# KD32F328CB register map
File version: 1.0
Registers are 32-bit, read-write, reset 0x0 unless marked. A register's access mark holds for its fields unless they carry their own. Offsets are from the block's base; [hi:lo] are bit positions.

## RCC — Reset and clock control
Base 0x40021000
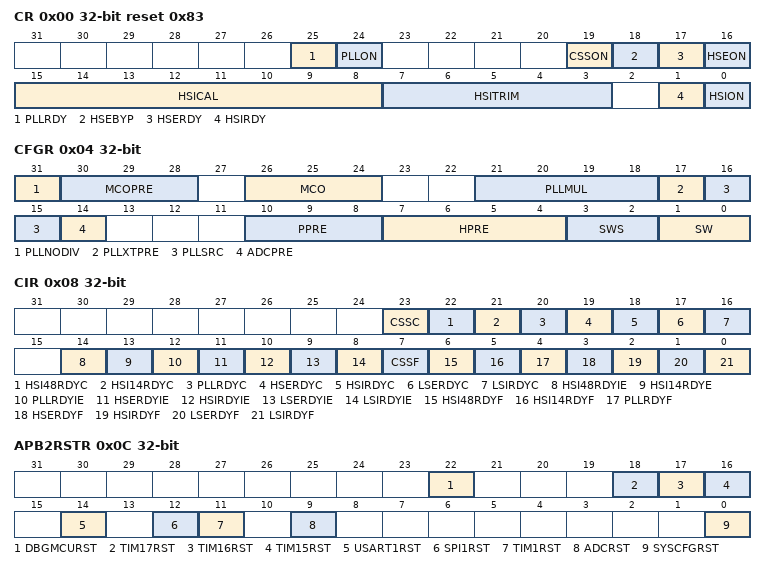
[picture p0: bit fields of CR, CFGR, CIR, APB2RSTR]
0x00 CR access per field reset 0x83 — Clock control register
  [25] PLLRDY ro — PLL clock ready flag
  [24] PLLON rw — PLL enable
  [19] CSSON rw — Clock Security System enable
  [18] HSEBYP rw — External High Speed clock Bypass
  [17] HSERDY ro — External High Speed clock ready flag
  [16] HSEON rw — External High Speed clock enable
  [15:8] HSICAL ro — Internal High Speed clock Calibration
  [7:3] HSITRIM rw — Internal High Speed clock trimming
  [1] HSIRDY ro — Internal High Speed clock ready flag
  [0] HSION rw — Internal High Speed clock enable
0x04 CFGR access per field — Clock configuration register (RCC_CFGR)
  [31] PLLNODIV rw — PLL clock not divided for MCO
  [30:28] MCOPRE rw — Microcontroller Clock Output Prescaler
  [26:24] MCO rw — Microcontroller clock output
  [21:18] PLLMUL rw — PLL Multiplication Factor
  [17] PLLXTPRE rw — HSE divider for PLL entry
  [16:15] PLLSRC rw — PLL input clock source
  [14] ADCPRE rw — ADC prescaler
  [10:8] PPRE rw — APB Low speed prescaler (APB1)
  [7:4] HPRE rw — AHB prescaler
  [3:2] SWS ro — System Clock Switch Status
  [1:0] SW rw — System clock Switch
0x08 CIR access per field — Clock interrupt register (RCC_CIR)
  [23] CSSC wo — Clock security system interrupt clear
  [22] HSI48RDYC wo — HSI48 Ready Interrupt Clear
  [21] HSI14RDYC wo — HSI 14 MHz Ready Interrupt Clear
  [20] PLLRDYC wo — PLL Ready Interrupt Clear
  [19] HSERDYC wo — HSE Ready Interrupt Clear
  [18] HSIRDYC wo — HSI Ready Interrupt Clear
  [17] LSERDYC wo — LSE Ready Interrupt Clear
  [16] LSIRDYC wo — LSI Ready Interrupt Clear
  [14] HSI48RDYIE rw — HSI48 ready interrupt enable
  [13] HSI14RDYE rw — HSI14 ready interrupt enable
  [12] PLLRDYIE rw — PLL Ready Interrupt Enable
  [11] HSERDYIE rw — HSE Ready Interrupt Enable
  [10] HSIRDYIE rw — HSI Ready Interrupt Enable
  [9] LSERDYIE rw — LSE Ready Interrupt Enable
  [8] LSIRDYIE rw — LSI Ready Interrupt Enable
  [7] CSSF ro — Clock Security System Interrupt flag
  [6] HSI48RDYF ro — HSI48 ready interrupt flag
  [5] HSI14RDYF ro — HSI14 ready interrupt flag
  [4] PLLRDYF ro — PLL Ready Interrupt flag
  [3] HSERDYF ro — HSE Ready Interrupt flag
  [2] HSIRDYF ro — HSI Ready Interrupt flag
  [1] LSERDYF ro — LSE Ready Interrupt flag
  [0] LSIRDYF ro — LSI Ready Interrupt flag
0x0C APB2RSTR — APB2 peripheral reset register (RCC_APB2RSTR)
  [22] DBGMCURST — Debug MCU reset
  [18] TIM17RST — TIM17 timer reset
  [17] TIM16RST — TIM16 timer reset
  [16] TIM15RST — TIM15 timer reset
  [14] USART1RST — USART1 reset
  [12] SPI1RST — SPI 1 reset
  [11] TIM1RST — TIM1 timer reset
  [9] ADCRST — ADC interface reset
  [0] SYSCFGRST — SYSCFG and COMP reset
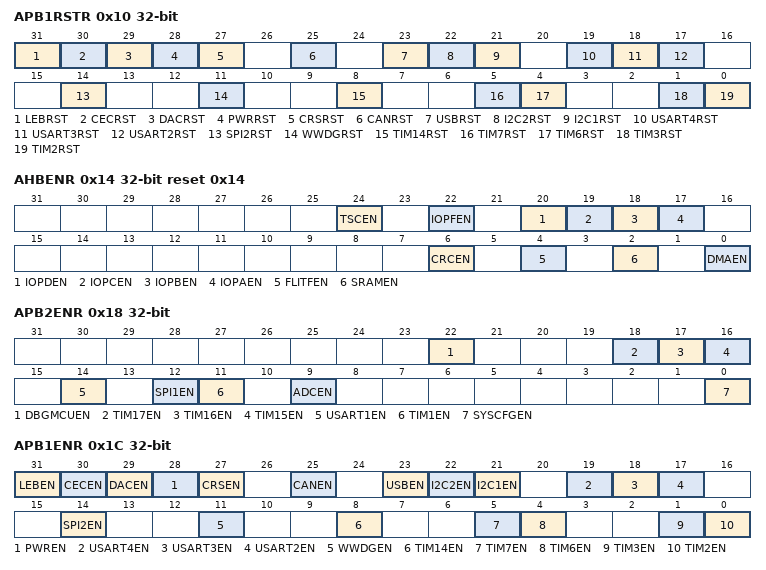
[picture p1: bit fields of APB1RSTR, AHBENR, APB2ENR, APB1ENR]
0x10 APB1RSTR — APB1 peripheral reset register (RCC_APB1RSTR)
  [31] LEBRST — LEB interface reset
  [30] CECRST — HDMI CEC reset
  [29] DACRST — DAC interface reset
  [28] PWRRST — Power interface reset
  [27] CRSRST — Clock Recovery System interface reset
  [25] CANRST — CAN interface reset
  [23] USBRST — USB interface reset
  [22] I2C2RST — I2C2 reset
  [21] I2C1RST — I2C1 reset
  [19] USART4RST — USART4 reset
  [18] USART3RST — USART3 reset
  [17] USART2RST — USART 2 reset
  [14] SPI2RST — SPI2 reset
  [11] WWDGRST — Window watchdog reset
  [8] TIM14RST — Timer 14 reset
  [5] TIM7RST — TIM7 timer reset
  [4] TIM6RST — Timer 6 reset
  [1] TIM3RST — Timer 3 reset
  [0] TIM2RST — Timer 2 reset
0x14 AHBENR reset 0x14 — AHB Peripheral Clock enable register (RCC_AHBENR)
  [24] TSCEN — Touch sensing controller clock enable
  [22] IOPFEN — I/O port F clock enable
  [20] IOPDEN — I/O port D clock enable
  [19] IOPCEN — I/O port C clock enable
  [18] IOPBEN — I/O port B clock enable
  [17] IOPAEN — I/O port A clock enable
  [6] CRCEN — CRC clock enable
  [4] FLITFEN — FLITF clock enable
  [2] SRAMEN — SRAM interface clock enable
  [0] DMAEN — DMA1 clock enable
0x18 APB2ENR — APB2 peripheral clock enable register (RCC_APB2ENR)
  [22] DBGMCUEN — MCU debug module clock enable
  [18] TIM17EN — TIM17 timer clock enable
  [17] TIM16EN — TIM16 timer clock enable
  [16] TIM15EN — TIM15 timer clock enable
  [14] USART1EN — USART1 clock enable
  [12] SPI1EN — SPI 1 clock enable
  [11] TIM1EN — TIM1 Timer clock enable
  [9] ADCEN — ADC 1 interface clock enable
  [0] SYSCFGEN — SYSCFG clock enable
0x1C APB1ENR — APB1 peripheral clock enable register (RCC_APB1ENR)
  [31] LEBEN — LEB interface clock enable
  [30] CECEN — HDMI CEC interface clock enable
  [29] DACEN — DAC interface clock enable
  [28] PWREN — Power interface clock enable
  [27] CRSEN — Clock Recovery System interface clock enable
  [25] CANEN — CAN interface clock enable
  [23] USBEN — USB interface clock enable
  [22] I2C2EN — I2C 2 clock enable
  [21] I2C1EN — I2C 1 clock enable
  [19] USART4EN — USART4 clock enable
  [18] USART3EN — USART3 clock enable
  [17] USART2EN — USART 2 clock enable
  [14] SPI2EN — SPI 2 clock enable
  [11] WWDGEN — Window watchdog clock enable
  [8] TIM14EN — Timer 14 clock enable
  [5] TIM7EN — TIM7 timer clock enable
  [4] TIM6EN — Timer 6 clock enable
  [1] TIM3EN — Timer 3 clock enable
  [0] TIM2EN — Timer 2 clock enable
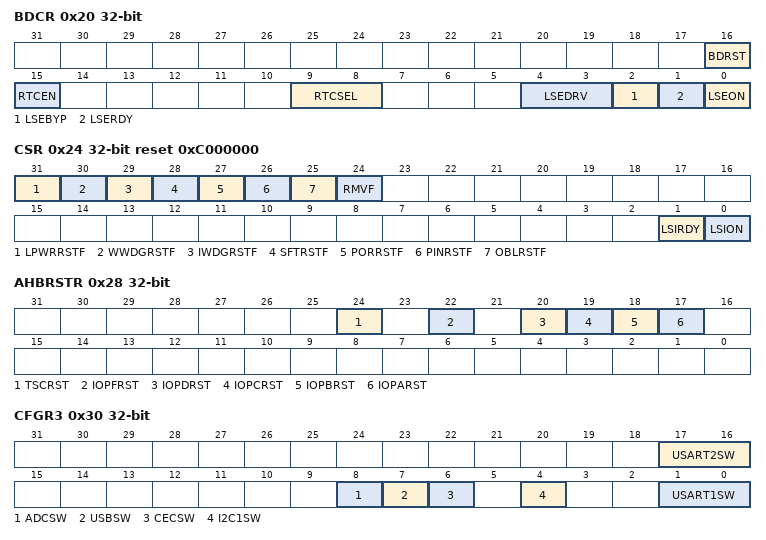
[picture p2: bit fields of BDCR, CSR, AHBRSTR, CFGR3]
0x20 BDCR access per field — Backup domain control register (RCC_BDCR)
  [16] BDRST rw — Backup domain software reset
  [15] RTCEN rw — RTC clock enable
  [9:8] RTCSEL rw — RTC clock source selection
  [4:3] LSEDRV rw — LSE oscillator drive capability
  [2] LSEBYP rw — External Low Speed oscillator bypass
  [1] LSERDY ro — External Low Speed oscillator ready
  [0] LSEON rw — External Low Speed oscillator enable
0x24 CSR access per field reset 0xC000000 — Control/status register (RCC_CSR)
  [31] LPWRRSTF rw — Low-power reset flag
  [30] WWDGRSTF rw — Window watchdog reset flag
  [29] IWDGRSTF rw — Independent watchdog reset flag
  [28] SFTRSTF rw — Software reset flag
  [27] PORRSTF rw — POR/PDR reset flag
  [26] PINRSTF rw — PIN reset flag
  [25] OBLRSTF rw — Option byte loader reset flag
  [24] RMVF rw — Remove reset flag
  [1] LSIRDY ro — Internal low speed oscillator ready
  [0] LSION rw — Internal low speed oscillator enable
0x28 AHBRSTR — AHB peripheral reset register
  [24] TSCRST — Touch sensing controller reset
  [22] IOPFRST — I/O port F reset
  [20] IOPDRST — I/O port D reset
  [19] IOPCRST — I/O port C reset
  [18] IOPBRST — I/O port B reset
  [17] IOPARST — I/O port A reset
0x2C CFGR2 — Clock configuration register 2
  [3:0] PREDIV — PREDIV division factor
0x30 CFGR3 — Clock configuration register 3
  [17:16] USART2SW — USART2 clock source selection
  [8] ADCSW — ADC clock source selection
  [7] USBSW — USB clock source selection
  [6] CECSW — HDMI CEC clock source selection
  [4] I2C1SW — I2C1 clock source selection
  [1:0] USART1SW — USART1 clock source selection
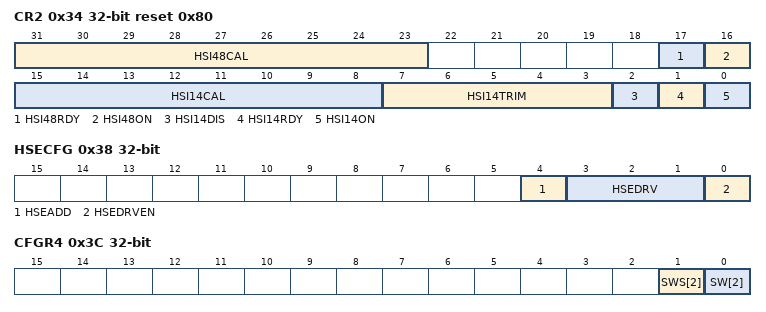
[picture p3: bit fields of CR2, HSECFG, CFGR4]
0x34 CR2 access per field reset 0x80 — Clock control register 2
  [31:23] HSI48CAL ro — HSI48 factory clock calibration
  [17] HSI48RDY ro — HSI48 clock ready flag
  [16] HSI48ON rw — HSI48 clock enable
  [15:8] HSI14CAL ro — HSI14 clock calibration
  [7:3] HSI14TRIM rw — HSI14 clock trimming
  [2] HSI14DIS rw — HSI14 clock request from ADC disable
  [1] HSI14RDY ro — HR14 clock ready flag
  [0] HSI14ON rw — HSI14 clock enable
0x38 HSECFG — HSE configuration register
  [4] HSEADD — HSE drive current add
  [3:1] HSEDRV — HSE drive capability
  [0] HSEDRVEN — HSE drive enable
0x3C CFGR4 — Clock configuration register4
  [1] SWS[2] — System clock Switch status
  [0] SW[2] — System clock Switch
0x40 TRIM — Internal High Speed clock trimming
  [0] HSICAL[8] — System clock Switch
